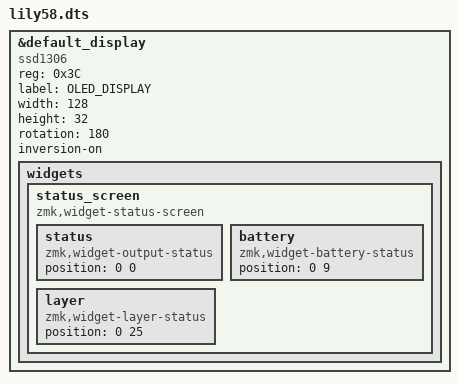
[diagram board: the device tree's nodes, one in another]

&default_display {
    compatible = "ssd1306";
    reg = <0x3C>;                    // I2C address of your SSD1306 OLED
    label = "OLED_DISPLAY";
    width = <128>;
    height = <32>;                   // or 64 depending on your OLED hardware
    rotation = <180>;                // Adjust rotation if needed
    inversion-on;                   // Optional: enable pixel inversion if desired
    status = "okay";

    widgets {
        status_screen {
            compatible = "zmk,widget-status-screen";
            status {
                compatible = "zmk,widget-output-status";
                position = <0 0>;
            };

            battery {
                compatible = "zmk,widget-battery-status";
                position = <0 9>;
            };
            layer {
                compatible = "zmk,widget-layer-status";
                position = <0 25>;
            };
        };
    };


};
